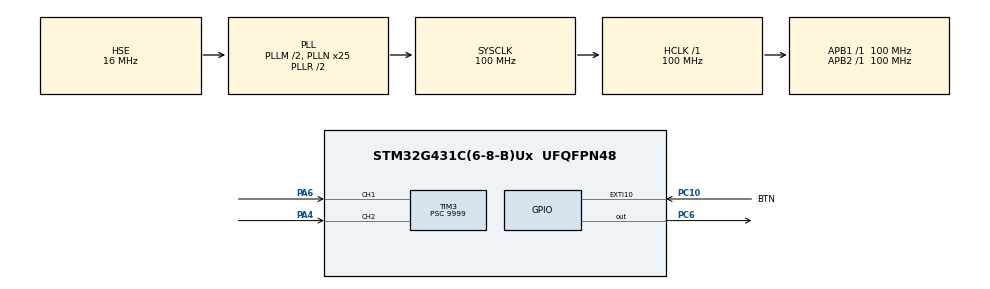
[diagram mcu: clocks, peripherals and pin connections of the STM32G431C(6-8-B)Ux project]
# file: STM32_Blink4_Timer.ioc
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Mcu.Family=STM32G4
Mcu.Name=STM32G431C(6-8-B)Ux
Mcu.Package=UFQFPN48
NVIC.EXTI15_10_IRQn=true\:0\:0\:false\:false\:true\:true\:true\:true
NVIC.PriorityGroup=NVIC_PRIORITYGROUP_4
NVIC.TIM3_IRQn=true\:0\:0\:false\:false\:true\:true\:true\:true
PA13.Mode=Serial_Wire
PA13.Signal=SYS_JTMS-SWDIO
PA14.Mode=Serial_Wire
PA14.Signal=SYS_JTCK-SWCLK
PA4.Signal=S_TIM3_CH2
PA6.Signal=S_TIM3_CH1
PC10.GPIO_Label=BTN
PC10.GPIO_ModeDefaultEXTI=GPIO_MODE_IT_RISING
PC10.GPIO_PuPd=GPIO_PULLUP
PC10.Signal=GPXTI10
PC6.Signal=GPIO_Output
PF0-OSC_IN.Mode=HSE-External-Oscillator
PF0-OSC_IN.Signal=RCC_OSC_IN
PF1-OSC_OUT.Mode=HSE-External-Oscillator
PF1-OSC_OUT.Signal=RCC_OSC_OUT
ProjectManager.HeapSize=0x200
ProjectManager.StackSize=0x400
ProjectManager.TargetToolchain=STM32CubeIDE
RCC.ADC12Freq_Value=100000000
RCC.AHBFreq_Value=100000000
RCC.APB1Freq_Value=100000000
RCC.APB1TimFreq_Value=100000000
RCC.APB2Freq_Value=100000000
RCC.APB2TimFreq_Value=100000000
RCC.CortexFreq_Value=100000000
RCC.EXTERNAL_CLOCK_VALUE=12288000
RCC.HCLKFreq_Value=100000000
RCC.HSE_VALUE=16000000
RCC.HSI48_VALUE=48000000
RCC.HSI_VALUE=16000000
RCC.LSE_VALUE=32768
RCC.PLLM=RCC_PLLM_DIV2
RCC.PLLN=25
RCC.PLLSourceVirtual=RCC_PLLSOURCE_HSE
RCC.SYSCLKFreq_VALUE=100000000
RCC.SYSCLKSource=RCC_SYSCLKSOURCE_PLLCLK
RCC.USBFreq_Value=100000000
RCC.VCOOutputFreq_Value=200000000
SH.S_TIM3_CH1.0=TIM3_CH1,Encoder_Interface
SH.S_TIM3_CH2.0=TIM3_CH2,Encoder_Interface
TIM3.PeriodNoDither=4999
TIM3.Prescaler=9999
VP_SYS_VS_DBSignals.Mode=DisableDeadBatterySignals
board=custom

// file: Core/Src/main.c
/* USER CODE BEGIN Header */
/**
  ******************************************************************************
  * @file           : main.c
  * @brief          : Main program body
  ******************************************************************************
  * @attention
  *
  * Copyright (c) 2026 STMicroelectronics.
  * All rights reserved.
  *
  * This software is licensed under terms that can be found in the LICENSE file
  * in the root directory of this software component.
  * If no LICENSE file comes with this software, it is provided AS-IS.
  *
  ******************************************************************************
  */
/* USER CODE END Header */
#include "main.h"

TIM_HandleTypeDef htim3;

/* USER CODE BEGIN PV */

uint16_t TICK_DELAY = 500 ;

/* USER CODE END PV */

void SystemClock_Config(void);
static void MX_GPIO_Init(void);
static void MX_TIM3_Init(void);

int main(void)
{

  /* MCU Configuration--------------------------------------------------------*/

  /* Reset of all peripherals, Initializes the Flash interface and the Systick. */
  HAL_Init();

  /* Configure the system clock */
  SystemClock_Config();

  /* Initialize all configured peripherals */
  MX_GPIO_Init();
  MX_TIM3_Init();
  /* USER CODE BEGIN 2 */

//  THIS FUNCTION DIDN"T EXIST ON STMG431CBU6
//  HAL_TIM_Base_Start_IT(&htim4);

  /* USER CODE END 2 */

  /* Infinite loop */
  /* USER CODE BEGIN WHILE */

  uint32_t now = 0, next_tick = TICK_DELAY;

  while (1)
  {
	  now = HAL_GetTick();

	  if (now >= next_tick) {

//		  printf("Tick %lu\n", now/1000);

		  next_tick = now + TICK_DELAY;
	  }
    /* USER CODE END WHILE */

  }
}

void SystemClock_Config(void)
{
  RCC_OscInitTypeDef RCC_OscInitStruct = {0};
  RCC_ClkInitTypeDef RCC_ClkInitStruct = {0};

  /** Configure the main internal regulator output voltage
  */
  HAL_PWREx_ControlVoltageScaling(PWR_REGULATOR_VOLTAGE_SCALE1);

  /** Initializes the RCC Oscillators according to the specified parameters
  * in the RCC_OscInitTypeDef structure.
  */
  RCC_OscInitStruct.OscillatorType = RCC_OSCILLATORTYPE_HSE;
  RCC_OscInitStruct.HSEState = RCC_HSE_ON;
  RCC_OscInitStruct.PLL.PLLState = RCC_PLL_ON;
  RCC_OscInitStruct.PLL.PLLSource = RCC_PLLSOURCE_HSE;
  RCC_OscInitStruct.PLL.PLLM = RCC_PLLM_DIV2;
  RCC_OscInitStruct.PLL.PLLN = 25;
  RCC_OscInitStruct.PLL.PLLP = RCC_PLLP_DIV2;
  RCC_OscInitStruct.PLL.PLLQ = RCC_PLLQ_DIV2;
  RCC_OscInitStruct.PLL.PLLR = RCC_PLLR_DIV2;
  if (HAL_RCC_OscConfig(&RCC_OscInitStruct) != HAL_OK)
  {
    Error_Handler();
  }

  /** Initializes the CPU, AHB and APB buses clocks
  */
  RCC_ClkInitStruct.ClockType = RCC_CLOCKTYPE_HCLK|RCC_CLOCKTYPE_SYSCLK
                              |RCC_CLOCKTYPE_PCLK1|RCC_CLOCKTYPE_PCLK2;
  RCC_ClkInitStruct.SYSCLKSource = RCC_SYSCLKSOURCE_PLLCLK;
  RCC_ClkInitStruct.AHBCLKDivider = RCC_SYSCLK_DIV1;
  RCC_ClkInitStruct.APB1CLKDivider = RCC_HCLK_DIV1;
  RCC_ClkInitStruct.APB2CLKDivider = RCC_HCLK_DIV1;

  if (HAL_RCC_ClockConfig(&RCC_ClkInitStruct, FLASH_LATENCY_3) != HAL_OK)
  {
    Error_Handler();
  }
}

static void MX_TIM3_Init(void)
{

  TIM_Encoder_InitTypeDef sConfig = {0};
  TIM_MasterConfigTypeDef sMasterConfig = {0};

  htim3.Instance = TIM3;
  htim3.Init.Prescaler = 9999;
  htim3.Init.CounterMode = TIM_COUNTERMODE_UP;
  htim3.Init.Period = 4999;
  htim3.Init.ClockDivision = TIM_CLOCKDIVISION_DIV1;
  htim3.Init.AutoReloadPreload = TIM_AUTORELOAD_PRELOAD_DISABLE;
  sConfig.EncoderMode = TIM_ENCODERMODE_TI1;
  sConfig.IC1Polarity = TIM_ICPOLARITY_RISING;
  sConfig.IC1Selection = TIM_ICSELECTION_DIRECTTI;
  sConfig.IC1Prescaler = TIM_ICPSC_DIV1;
  sConfig.IC1Filter = 0;
  sConfig.IC2Polarity = TIM_ICPOLARITY_RISING;
  sConfig.IC2Selection = TIM_ICSELECTION_DIRECTTI;
  sConfig.IC2Prescaler = TIM_ICPSC_DIV1;
  sConfig.IC2Filter = 0;
  if (HAL_TIM_Encoder_Init(&htim3, &sConfig) != HAL_OK)
  {
    Error_Handler();
  }
  sMasterConfig.MasterOutputTrigger = TIM_TRGO_RESET;
  sMasterConfig.MasterSlaveMode = TIM_MASTERSLAVEMODE_DISABLE;
  if (HAL_TIMEx_MasterConfigSynchronization(&htim3, &sMasterConfig) != HAL_OK)
  {
    Error_Handler();
  }

}

static void MX_GPIO_Init(void)
{
  GPIO_InitTypeDef GPIO_InitStruct = {0};

  /* GPIO Ports Clock Enable */
  __HAL_RCC_GPIOF_CLK_ENABLE();
  __HAL_RCC_GPIOA_CLK_ENABLE();
  __HAL_RCC_GPIOC_CLK_ENABLE();

  /*Configure GPIO pin Output Level */
  HAL_GPIO_WritePin(GPIOC, GPIO_PIN_6, GPIO_PIN_RESET);

  /*Configure GPIO pin : PC6 */
  GPIO_InitStruct.Pin = GPIO_PIN_6;
  GPIO_InitStruct.Mode = GPIO_MODE_OUTPUT_PP;
  GPIO_InitStruct.Pull = GPIO_NOPULL;
  GPIO_InitStruct.Speed = GPIO_SPEED_FREQ_LOW;
  HAL_GPIO_Init(GPIOC, &GPIO_InitStruct);

  /*Configure GPIO pin : BTN_Pin */
  GPIO_InitStruct.Pin = BTN_Pin;
  GPIO_InitStruct.Mode = GPIO_MODE_IT_RISING;
  GPIO_InitStruct.Pull = GPIO_PULLUP;
  HAL_GPIO_Init(BTN_GPIO_Port, &GPIO_InitStruct);

  /* EXTI interrupt init*/
  HAL_NVIC_SetPriority(EXTI15_10_IRQn, 0, 0);
  HAL_NVIC_EnableIRQ(EXTI15_10_IRQn);

}

void Error_Handler(void)
{
  __disable_irq();
  while (1)
  {
  }
}
